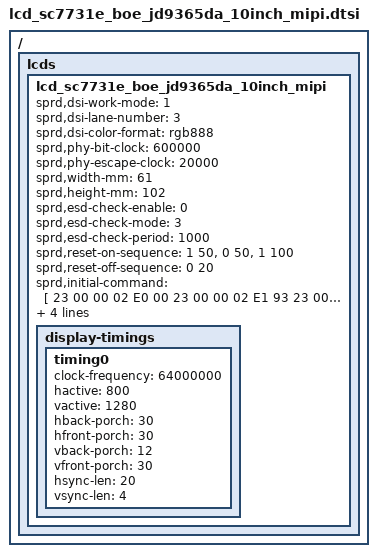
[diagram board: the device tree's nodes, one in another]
/ { lcds {
	lcd_sc7731e_boe_jd9365da_10inch_mipi: lcd_sc7731e_boe_jd9365da_10inch_mipi {

		sprd,dsi-work-mode = <1>;
		sprd,dsi-lane-number = <3>;
		sprd,dsi-color-format = "rgb888";

		sprd,phy-bit-clock = <600000>;
		sprd,phy-escape-clock = <20000>;

		sprd,width-mm = <61>;
		sprd,height-mm = <102>;

		sprd,esd-check-enable = <0>;
		sprd,esd-check-mode = <3>;
		sprd,esd-check-period = <1000>;
		/*sprd,esd-check-register = < 0A>;*/
		/*sprd,esd-check-value = < 9C>;*/

		sprd,reset-on-sequence = <1 50>, <0 50>, <1 100>;
		sprd,reset-off-sequence = <0 20>;

		sprd,initial-command = [
				23 00 00 02 E0 00
			23 00 00 02 E1 93
			23 00 00 02 E2 65
			23 00 00 02 E3 F8
			23 00 00 02 80 02


			23 00 00 02 E0 01
			23 00 00 02 00 00
			23 00 00 02 01 2C
			23 00 00 02 17 00
			23 00 00 02 0C 74
			23 00 00 02 18 AF
			23 00 00 02 19 01
			23 00 00 02 1A 00
			23 00 00 02 1B AF
			23 00 00 02 1C 01

			23 00 00 02 1F 3E
			23 00 00 02 20 28
			23 00 00 02 21 28
			23 00 00 02 22 7E
			23 00 00 02 35 26

			23 00 00 02 37 09
			23 00 00 02 38 04
			23 00 00 02 39 00
			23 00 00 02 3A 01
			23 00 00 02 3C 7C
			23 00 00 02 3D FF
			23 00 00 02 3E FF
			23 00 00 02 3F 7F

			23 00 00 02 40 06
			23 00 00 02 41 A0
			23 00 00 02 42 81
			23 00 00 02 43 08
			23 00 00 02 44 0B
			23 00 00 02 45 28
			23 00 00 02 55 01
			23 00 00 02 57 69
			23 00 00 02 59 0A
			23 00 00 02 5A 28
			23 00 00 02 5B 14

			23 00 00 02 5D 7C
			23 00 00 02 5E 65
			23 00 00 02 5F 55
			23 00 00 02 60 47
			23 00 00 02 61 43
			23 00 00 02 62 32
			23 00 00 02 63 34
			23 00 00 02 64 1C
			23 00 00 02 65 33
			23 00 00 02 66 31
			23 00 00 02 67 30
			23 00 00 02 68 4E
			23 00 00 02 69 3C
			23 00 00 02 6A 44
			23 00 00 02 6B 35
			23 00 00 02 6C 31
			23 00 00 02 6D 23
			23 00 00 02 6E 11
			23 00 00 02 6F 00
			23 00 00 02 70 7C
			23 00 00 02 71 65
			23 00 00 02 72 55
			23 00 00 02 73 47
			23 00 00 02 74 43
			23 00 00 02 75 32
			23 00 00 02 76 34
			23 00 00 02 77 1C
			23 00 00 02 78 33
			23 00 00 02 79 31
			23 00 00 02 7A 30
			23 00 00 02 7B 4E
			23 00 00 02 7C 3C
			23 00 00 02 7D 44
			23 00 00 02 7E 35
			23 00 00 02 7F 31
			23 00 00 02 80 23
			23 00 00 02 81 11
			23 00 00 02 82 00


			23 00 00 02 E0 02
			23 00 00 02 00 1E
			23 00 00 02 01 1E
			23 00 00 02 02 41
			23 00 00 02 03 41
			23 00 00 02 04 43
			23 00 00 02 05 43
			23 00 00 02 06 1F
			23 00 00 02 07 1F
			23 00 00 02 08 1F
			23 00 00 02 09 1F
			23 00 00 02 0A 1E
			23 00 00 02 0B 1E
			23 00 00 02 0C 1F
			23 00 00 02 0D 47
			23 00 00 02 0E 47
			23 00 00 02 0F 45
			23 00 00 02 10 45
			23 00 00 02 11 4B
			23 00 00 02 12 4B
			23 00 00 02 13 49
			23 00 00 02 14 49
			23 00 00 02 15 1F


			23 00 00 02 16 1E
			23 00 00 02 17 1E
			23 00 00 02 18 40
			23 00 00 02 19 40
			23 00 00 02 1A 42
			23 00 00 02 1B 42
			23 00 00 02 1C 1F
			23 00 00 02 1D 1F
			23 00 00 02 1E 1F
			23 00 00 02 1F 1F
			23 00 00 02 20 1E
			23 00 00 02 21 1E
			23 00 00 02 22 1F
			23 00 00 02 23 46
			23 00 00 02 24 46
			23 00 00 02 25 44
			23 00 00 02 26 44
			23 00 00 02 27 4A
			23 00 00 02 28 4A
			23 00 00 02 29 48
			23 00 00 02 2A 48
			23 00 00 02 2B 1F



			23 00 00 02 2C 1F
			23 00 00 02 2D 1F
			23 00 00 02 2E 42
			23 00 00 02 2F 42
			23 00 00 02 30 40
			23 00 00 02 31 40
			23 00 00 02 32 1E
			23 00 00 02 33 1E
			23 00 00 02 34 1F
			23 00 00 02 35 1F
			23 00 00 02 36 1E
			23 00 00 02 37 1E
			23 00 00 02 38 1F
			23 00 00 02 39 48
			23 00 00 02 3A 48
			23 00 00 02 3B 4A
			23 00 00 02 3C 4A
			23 00 00 02 3D 44
			23 00 00 02 3E 44
			23 00 00 02 3F 46
			23 00 00 02 40 46
			23 00 00 02 41 1F

			23 00 00 02 42 1F
			23 00 00 02 43 1F
			23 00 00 02 44 43
			23 00 00 02 45 43
			23 00 00 02 46 41
			23 00 00 02 47 41
			23 00 00 02 48 1E
			23 00 00 02 49 1E
			23 00 00 02 4A 1E
			23 00 00 02 4B 1F
			23 00 00 02 4C 1E
			23 00 00 02 4D 1E
			23 00 00 02 4E 1F
			23 00 00 02 4F 49
			23 00 00 02 50 49
			23 00 00 02 51 4B
			23 00 00 02 52 4B
			23 00 00 02 53 45
			23 00 00 02 54 45
			23 00 00 02 55 47
			23 00 00 02 56 47
			23 00 00 02 57 1F


			23 00 00 02 58 40
			23 00 00 02 5B 30
			23 00 00 02 5C 03
			23 00 00 02 5D 30
			23 00 00 02 5E 01
			23 00 00 02 5F 02
			23 00 00 02 63 14
			23 00 00 02 64 6A
			23 00 00 02 67 73
			23 00 00 02 68 05
			23 00 00 02 69 14
			23 00 00 02 6A 6A
			23 00 00 02 6B 08

			23 00 00 02 6C 00
			23 00 00 02 6D 06
			23 00 00 02 6E 00
			23 00 00 02 6F 88

			23 00 00 02 77 DD
			23 00 00 02 79 0E
			23 00 00 02 7A 03
			23 00 00 02 7D 14
			23 00 00 02 7E 6A


			23 00 00 02 E0 04
			23 00 00 02 09 11
			23 00 00 02 0E 48
			23 00 00 02 2D 03
			23 00 00 02 2B 08
			23 00 00 02 2E 03


			23 00 00 02 E0 00

			23 00 00 02 E6 02
			23 00 00 02 E7 0C
			
			13	78	00	01	11  	// SLPOUT
			13	78	00	01	29  	// DSPON
			//--- TE----//
			23  00  00  02  35  00
			];
		sprd,sleep-in-command = [
			13 0A 00 01 28
			13 78 00 01 10
			];
		sprd,sleep-out-command = [
			13 78 00 01 11
			13 64 00 01 29
			];

		display-timings {
			timing0 {
			clock-frequency = <64000000>;
			hactive = <800>;
			vactive = <1280>;
			hback-porch = <30>;
			hfront-porch = <30>;
			vback-porch = <12>;
			vfront-porch = <30>;
			hsync-len = <20>;
			vsync-len = <4>;
			};
		};
	};
};};

